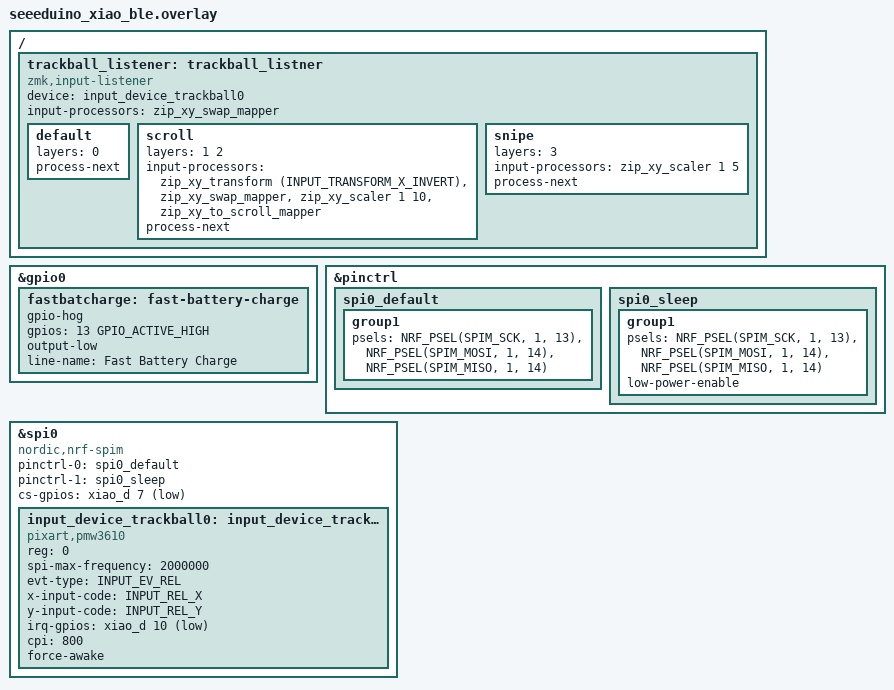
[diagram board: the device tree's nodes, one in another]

/**
 * Generated by Shield Wizard for ZMK
 * Applies to shield "pterontb_trackball" with board "seeeduino_xiao_ble" only
 */

&gpio0 {
    fastbatcharge: fast-battery-charge {
        gpio-hog;
        gpios = <13 GPIO_ACTIVE_HIGH>;
        output-low;
        line-name = "Fast Battery Charge";
    };
};
//
// ======== spi0 ========
//

// pin control for spi0
// - SCK on D8
// - MOSI on D9
// - MISO on D9
&pinctrl {
    /* configuration for spi0 device, default state */
    spi0_default: spi0_default {
        group1 {
            psels = <NRF_PSEL(SPIM_SCK, 1, 13)>,
                    <NRF_PSEL(SPIM_MOSI, 1, 14)>,
                    <NRF_PSEL(SPIM_MISO, 1, 14)>;
        };
    };
    /* configuration for spi0 device, sleep state */
    spi0_sleep: spi0_sleep {
        group1 {
            psels = <NRF_PSEL(SPIM_SCK, 1, 13)>,
                    <NRF_PSEL(SPIM_MOSI, 1, 14)>,
                    <NRF_PSEL(SPIM_MISO, 1, 14)>;
            low-power-enable;
        };
    };
};
&spi0 {
  compatible = "nordic,nrf-spim";
  status = "okay";
  pinctrl-0 = <&spi0_default>;
  pinctrl-1 = <&spi0_sleep>;
  pinctrl-names = "default", "sleep";
};

// devices on spi0

// CS pins for devices on spi0
&spi0 {
    cs-gpios = <&xiao_d 7 GPIO_ACTIVE_LOW>;
};

#include <zephyr/dt-bindings/input/input-event-codes.h>
#include <dt-bindings/zmk/input_transform.h>
#include <input/processors.dtsi>

&spi0 {
    input_device_trackball0: input_device_trackball0@0 {
        status = "okay";
        compatible = "pixart,pmw3610";
        reg = <0>;
        spi-max-frequency = <2000000>;
        evt-type = <INPUT_EV_REL>;
        x-input-code = <INPUT_REL_X>;
        y-input-code = <INPUT_REL_Y>;
        irq-gpios = <&xiao_d 10 (GPIO_ACTIVE_LOW | GPIO_PULL_UP)>;
        cpi = <800>;
        force-awake;
    };
};

/ {
  trackball_listener: trackball_listner {
    compatible = "zmk,input-listener";
    device = <&input_device_trackball0>;
    input-processors = <&zip_xy_swap_mapper>;

    default {
        layers = <0>;
        process-next;
    };
    scroll {
        layers = <1 2>;
        input-processors = <&zip_xy_transform (INPUT_TRANSFORM_X_INVERT)>, <&zip_xy_swap_mapper>, <&zip_xy_scaler 1 10>, <&zip_xy_to_scroll_mapper>;
        process-next;
    };
    snipe {
        layers = <3>;
        input-processors = <&zip_xy_scaler 1 5>;
        process-next;
    };
  };
}; 
